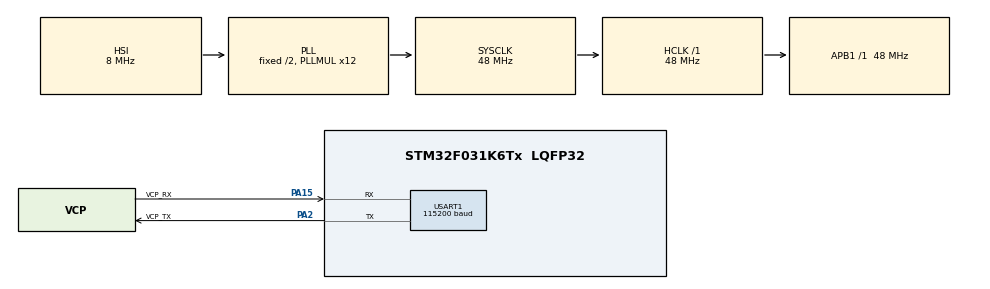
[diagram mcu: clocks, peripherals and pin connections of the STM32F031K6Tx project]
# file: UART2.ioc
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Mcu.Family=STM32F0
Mcu.Name=STM32F031K6Tx
Mcu.Package=LQFP32
NVIC.USART1_IRQn=true\:0\:0\:false\:false\:true\:true\:true
PA13.GPIO_Label=SWDIO
PA13.Mode=Serial_Wire
PA13.Signal=SYS_SWDIO
PA14.GPIO_Label=SWCLK
PA14.Mode=Serial_Wire
PA14.Signal=SYS_SWCLK
PA15.GPIO_Label=VCP_RX
PA15.Mode=Asynchronous
PA15.Signal=USART1_RX
PA2.GPIO_Label=VCP_TX
PA2.Mode=Asynchronous
PA2.Signal=USART1_TX
PF0-OSC_IN.Mode=HSE-External-Clock-Source
PF0-OSC_IN.Signal=RCC_OSC_IN
ProjectManager.HeapSize=0x200
ProjectManager.StackSize=0x400
ProjectManager.TargetToolchain=STM32CubeIDE
RCC.AHBFreq_Value=48000000
RCC.APB1Freq_Value=48000000
RCC.APB1TimFreq_Value=48000000
RCC.HCLKFreq_Value=48000000
RCC.PLLMUL=RCC_PLL_MUL12
RCC.SYSCLKFreq_VALUE=48000000
RCC.SYSCLKSource=RCC_SYSCLKSOURCE_PLLCLK
USART1.BaudRate=115200
USART1.VirtualMode-Asynchronous=VM_ASYNC
board=NUCLEO-F031K6

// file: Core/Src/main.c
/* USER CODE BEGIN Header */
typedef int INT;
typedef INT BOOL;
#define TRUE 1
#define FALSE 0
/**
  ******************************************************************************
  * @file           : main.c
  * @brief          : Main program body
  ******************************************************************************
  * @attention
  *
  * <h2><center>&copy; Copyright (c) 2019 STMicroelectronics.
  * All rights reserved.</center></h2>
  *
  * This software component is licensed by ST under BSD 3-Clause license,
  * the "License"; You may not use this file except in compliance with the
  * License. You may obtain a copy of the License at:
  *                        opensource.org/licenses/BSD-3-Clause
  *
  ******************************************************************************
  */
/* USER CODE END Header */

#include "main.h"

UART_HandleTypeDef huart1;

/* USER CODE BEGIN PV */
uint8_t str[];
int onn, off, f, q = 0; //flags
double frequency, quantity = 0;
/* USER CODE END PV */

void SystemClock_Config(void);
static void MX_GPIO_Init(void);
static void MX_USART1_UART_Init(void);
/* USER CODE BEGIN PFP */

BOOL IsON(uint8_t* BitsON);
BOOL IsOFF(uint8_t* BitsOFF);
BOOL IsFR(uint8_t* BitsFR);
BOOL IsQ(uint8_t* BitsQ);
double Number(uint8_t* BitsN);

/* USER CODE END PFP */

int main(void)
{

  /* MCU Configuration--------------------------------------------------------*/

  /* Reset of all peripherals, Initializes the Flash interface and the Systick. */
  HAL_Init();

  /* Configure the system clock */
  SystemClock_Config();

  /* Initialize all configured peripherals */
  MX_GPIO_Init();
  MX_USART1_UART_Init();

  /* Infinite loop */
  while (1)
  {

    /* USER CODE BEGIN 3 */

      HAL_UART_Receive_IT(&huart1, (uint8_t*)str, 3); // receiving data

      /* cheack for ON or OFF */

      if(IsON((uint8_t*)str)) {
        onn = 1;
        off = 0;
      } else if(IsOFF((uint8_t*)str)) {
        onn = 0;
        off = 1;
      }

        /*checking for “frequency” or “quantity”*/
      if (onn == 1) {

      if(IsFR((uint8_t*)str)) {
        f = 1;
        q = 0;
      } else if(IsQ((uint8_t*)str)) {
        q = 1;
        f = 0;
      } else {
        for (int i = 0; i < 3; i ++) {
          str[i] = 0;
        }
       }

      /*  frequency calculation */
        if(f == 1){

        frequency=Number((uint8_t*)str);

        HAL_GPIO_TogglePin(GPIOB, GPIO_PIN_3); // switch led
        HAL_Delay(1000/frequency);       //delay
        }

        /* quantity calculation */
        if(q == 1){

        quantity=Number((uint8_t*)str);

        for(int i =0; i < (quantity)-1; i++ )
        {
        HAL_GPIO_TogglePin(GPIOB, GPIO_PIN_3);
        HAL_Delay(300);
        }

        HAL_GPIO_WritePin(GPIOB, GPIO_PIN_3, GPIO_PIN_RESET); //reset led3
         for (int i = 0; i < 3; i ++) {
         str[i] = 0;
        }

        off = 1;
        onn = 0;
        q = 0;
      }

      if (f==0) {
        HAL_GPIO_TogglePin(GPIOB, GPIO_PIN_3);
        HAL_Delay(500);
      }
      }

      //shutdown

      if (off == 1) {
      HAL_GPIO_WritePin(GPIOB, GPIO_PIN_3, GPIO_PIN_RESET);
      f = 0;
      for (int i = 0; i < 3; i ++) {
      str[i] = 0;
        }
      off = 0;
      }

  }
  /* USER CODE END 3 */
}

void SystemClock_Config(void)
{
  RCC_OscInitTypeDef RCC_OscInitStruct = {0};
  RCC_ClkInitTypeDef RCC_ClkInitStruct = {0};
  RCC_PeriphCLKInitTypeDef PeriphClkInit = {0};

  /** Initializes the CPU, AHB and APB busses clocks
  */
  RCC_OscInitStruct.OscillatorType = RCC_OSCILLATORTYPE_HSI;
  RCC_OscInitStruct.HSIState = RCC_HSI_ON;
  RCC_OscInitStruct.HSICalibrationValue = RCC_HSICALIBRATION_DEFAULT;
  RCC_OscInitStruct.PLL.PLLState = RCC_PLL_ON;
  RCC_OscInitStruct.PLL.PLLSource = RCC_PLLSOURCE_HSI;
  RCC_OscInitStruct.PLL.PLLMUL = RCC_PLL_MUL12;
  RCC_OscInitStruct.PLL.PREDIV = RCC_PREDIV_DIV1;
  if (HAL_RCC_OscConfig(&RCC_OscInitStruct) != HAL_OK)
  {
    Error_Handler();
  }
  /** Initializes the CPU, AHB and APB busses clocks
  */
  RCC_ClkInitStruct.ClockType = RCC_CLOCKTYPE_HCLK|RCC_CLOCKTYPE_SYSCLK
                              |RCC_CLOCKTYPE_PCLK1;
  RCC_ClkInitStruct.SYSCLKSource = RCC_SYSCLKSOURCE_PLLCLK;
  RCC_ClkInitStruct.AHBCLKDivider = RCC_SYSCLK_DIV1;
  RCC_ClkInitStruct.APB1CLKDivider = RCC_HCLK_DIV1;

  if (HAL_RCC_ClockConfig(&RCC_ClkInitStruct, FLASH_LATENCY_1) != HAL_OK)
  {
    Error_Handler();
  }
  PeriphClkInit.PeriphClockSelection = RCC_PERIPHCLK_USART1;
  PeriphClkInit.Usart1ClockSelection = RCC_USART1CLKSOURCE_PCLK1;
  if (HAL_RCCEx_PeriphCLKConfig(&PeriphClkInit) != HAL_OK)
  {
    Error_Handler();
  }
}

static void MX_USART1_UART_Init(void)
{

  huart1.Instance = USART1;
  huart1.Init.BaudRate = 115200;
  huart1.Init.WordLength = UART_WORDLENGTH_8B;
  huart1.Init.StopBits = UART_STOPBITS_1;
  huart1.Init.Parity = UART_PARITY_NONE;
  huart1.Init.Mode = UART_MODE_TX_RX;
  huart1.Init.HwFlowCtl = UART_HWCONTROL_NONE;
  huart1.Init.OverSampling = UART_OVERSAMPLING_16;
  huart1.Init.OneBitSampling = UART_ONE_BIT_SAMPLE_DISABLE;
  huart1.AdvancedInit.AdvFeatureInit = UART_ADVFEATURE_NO_INIT;
  if (HAL_UART_Init(&huart1) != HAL_OK)
  {
    Error_Handler();
  }

}

static void MX_GPIO_Init(void)
{
  GPIO_InitTypeDef GPIO_InitStruct = {0};

  /* GPIO Ports Clock Enable */
  __HAL_RCC_GPIOA_CLK_ENABLE();
  __HAL_RCC_GPIOB_CLK_ENABLE();

  /*Configure GPIO pin Output Level */
  HAL_GPIO_WritePin(GPIOB, GPIO_PIN_3, GPIO_PIN_RESET);

  /*Configure GPIO pin : PB3 */
  GPIO_InitStruct.Pin = GPIO_PIN_3;
  GPIO_InitStruct.Mode = GPIO_MODE_OUTPUT_PP;
  GPIO_InitStruct.Pull = GPIO_NOPULL;
  GPIO_InitStruct.Speed = GPIO_SPEED_FREQ_LOW;
  HAL_GPIO_Init(GPIOB, &GPIO_InitStruct);

}

/* USER CODE BEGIN 4 */

BOOL IsON(uint8_t* str)
{
	return (BOOL)(str[0] == 0x6F && str[1] == 0x6E && str[2] == 0x6E);
}
BOOL IsOFF(uint8_t* str)
{
	return (BOOL)(str[0] == 0x6F && str[1] == 0x6E && str[2] == 0x6E);
}
BOOL IsFR(uint8_t* str)
{
	return (BOOL)(str[2] == 0x71 && (str[0] >= 0x30 && str[0] <= 0x39) && (str[1] >= 0x30 && str[1] <= 0x39));
}
BOOL IsQ(uint8_t* str)
{
	return (BOOL)(str[2] == 0x71 && (str[0] >= 0x30 && str[0] <= 0x39) && (str[1] >= 0x30 && str[1] <= 0x39));
}
double Number(uint8_t* str)
{
	double res = 0;
	if (str[0] == 0x30) {
	        res = (str[1] - 48)*2;
	        return res;
	}
	if (str[0] > 0x30){
	        res = ((str[0] - 48)*10 + (str[1] - 48))*2;
	        return res;
	}
}

/* USER CODE END 4 */

void Error_Handler(void)
{
}

/************************ (C) COPYRIGHT STMicroelectronics *****END OF FILE****/
